# STM32L4R5 register map
File version: 2.4
CPU: CM4 r0p1, little endian, MPU, FPU, 4 interrupt priority bits
Registers are 32-bit, read-write, reset 0x0 unless marked. A register's access mark holds for its fields unless they carry their own. Offsets are from the block's base; [hi:lo] are bit positions; {n}, {i} and the like mark numbered series.

## FLASH
Base 0x40022000
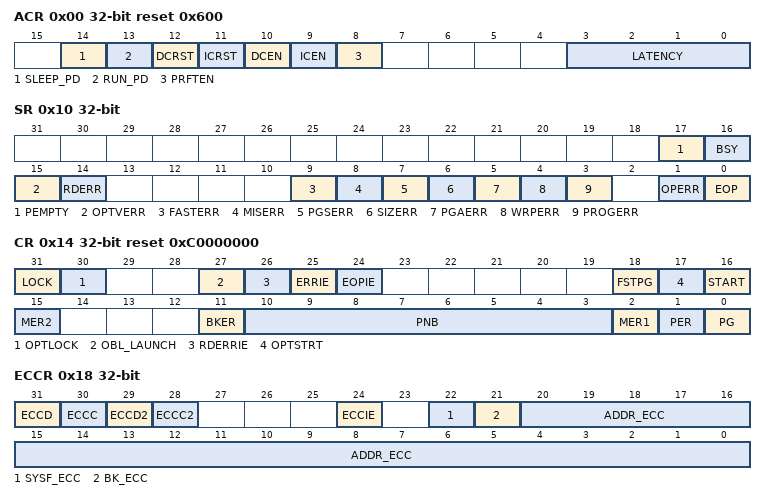
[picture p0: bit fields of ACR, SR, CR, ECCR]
0x00 ACR reset 0x600 — Access control register
  [14] SLEEP_PD — Flash Power-down mode during Low-power sleep mode
    0=Idle (Flash in idle mode during Sleep and Low-power sleep modes); 1=PowerDown (Flash in Power-down mode during Sleep and Low-power sleep modes)
  [13] RUN_PD — Flash Power-down mode during Low-power run mode
    0=Idle (Flash in idle mode); 1=PowerDown (Flash in Power-down mode)
  [12] DCRST — Data cache reset
    0=NotReset (Data cache is not reset); 1=Reset (Data cache is reset)
  [11] ICRST — Instruction cache reset
    0=NotReset (Instruction cache is not reset); 1=Reset (Instruction cache is reset)
  [10] DCEN — Data cache enable
    0=Disabled (Data cache is disabled); 1=Enabled (Data cache is enabled)
  [9] ICEN — Instruction cache enable
    0=Disabled (Instruction cache is disabled); 1=Enabled (Instruction cache is enabled)
  [8] PRFTEN — Prefetch enable
    0=Disabled (Prefetch is disabled); 1=Enabled (Prefetch is enabled)
  [3:0] LATENCY
    {v}=WS{v} ({v} wait states) (v=0..15)
0x04 PDKEYR wo — Power down key register
  [31:0] PDKEYR — RUN_PD in FLASH_ACR key
0x08 KEYR wo — Flash key register
0x0C OPTKEYR wo — Option byte key register
  [31:0] OPTKEYR — Option byte key
0x10 SR access per field — Status register
  [17] PEMPTY rw — Program EMPTY
    0=Toggling (The bit value is toggling); 1=NoEffect
  [16] BSY ro — Busy
    0=NotBusy; 1=Busy
  [15] OPTVERR rw — Option validity error
    on read: 0=NoError; 1=Error (Set by hardware when the options read may not be the one configured by the user. If option haven’t been properly loaded, OPTVERR is set again after each system reset) | on write: 1=Cleared by writing 1
  [14] RDERR rw — PCROP read error
    on read: 0=NoError; 1=Error (Set by hardware when an address to be read through the D-bus belongs to a read protected area of the Flash (PCROP protection)) | on write: 1=Cleared by writing 1
  [9] FASTERR rw — Fast programming error
    on read: 0=NoError; 1=Error (Set by hardware when a fast programming sequence (activated by FSTPG) is interrupted due to an error (alignment, size, write protection or data miss). The corresponding status bit (PGAERR, SIZERR, WRPERR or MISSERR) is set at the same time) | on write: 1=Cleared by writing 1
  [8] MISERR rw — Fast programming data miss error
    on read: 0=NoError; 1=Error (In fast programming mode, 32 double words must be sent to Flash successively, and the new data must be sent to the Flash logic control before the current data is fully programmed. MISSERR is set by hardware when the new data is not present in time) | on write: 1=Cleared by writing 1
  [7] PGSERR rw — Programming sequence error
    on read: 0=NoError; 1=Error (Set by hardware when a write access to the Flash memory is performed by the code while PG or FSTPG have not been set previously. Set also by hardware when PROGERR, SIZERR, PGAERR, WRPERR, MISSERR or FASTERR is set due to a previous programming error. Set also when trying to perform bank erase when DBANK=0 (or DB1M = 0)) | on write: 1=Cleared by writing 1
  [6] SIZERR rw — Size error
    on read: 0=NoError; 1=Error (Set by hardware when the size of the access is a byte or half-word during a program or a fast program sequence. Only double word programming is allowed (consequently: word access)) | on write: 1=Cleared by writing 1
  [5] PGAERR rw — Programming alignment error
    on read: 0=NoError; 1=Error (Set by hardware when the data to program cannot be contained in the same 64-bit Flash memory row in case of standard programming, or if there is a change of page during fast programming) | on write: 1=Cleared by writing 1
  [4] WRPERR rw — Write protected error
    on read: 0=NoError; 1=Error (Set by hardware when an address to be erased/programmed belongs to a writeprotected part (by WRP, PCROP or RDP level 1) of the Flash memory) | on write: 1=Cleared by writing 1
  [3] PROGERR rw — Programming error
    on read: 0=NoError; 1=Error (Set by hardware when a double-word address to be programmed contains a value different from '0xFFFF FFFF' before programming, except if the data to write is '0x0000 0000') | on write: 1=Cleared by writing 1
  [1] OPERR rw — Operation error
    on read: 0=NoError; 1=Error (Set by hardware when a Flash memory operation (program / erase) completes unsuccessfully) | on write: 1=Cleared by writing 1
  [0] EOP rw — End of operation
    on read: 0=NoError; 1=Error (Set by hardware when one or more Flash memory operation (programming / erase) has been completed successfully) | on write: 1=Cleared by writing 1
0x14 CR reset 0xC0000000 — Flash control register
  [31] LOCK — FLASH_CR Lock
    on read: 0=Unlocked (FLASH_CR register is unlocked); 1=Locked (FLASH_CR register is locked) | on write: 1=Set (This bit is set only. When set, the FLASH_CR register is locked)
  [30] OPTLOCK — Options Lock
    on read: 0=Unlocked (Option page is unlocked); 1=Locked (All bits concerning user option in FLASH_CR register and so option page are locked) | on write: 1=Set (This bit is set only. When set, all bits concerning user option in FLASH_CR register and so option page are locked)
  [27] OBL_LAUNCH — Force the option byte loading
    on read: 0=Complete (Option byte loading complete); 1=Requested (Option byte loading requested) | on write: 1=Set (Force option byte reloading)
  [26] RDERRIE — PCROP read error interrupt enable
    0=Disabled (PCROP read error interrupt disabled); 1=Enabled (PCROP read error interrupt enabled)
  [25] ERRIE — Error interrupt enable
    0=Disabled (Error interrupt generation disabled); 1=Enabled (Error interrupt generation enabled)
  [24] EOPIE — End of operation interrupt enable
    0=Disabled (End of operation interrupt disabled); 1=Enabled (End of operation interrupt enabled)
  [18] FSTPG — Fast programming
    0=Disabled (Fast programming disabled); 1=Enabled (Fast programming enabled)
  [17] OPTSTRT — Options modification start
    on read: 0=Complete (Cleared when BSY bit is cleared in SR); 1=Requested (Options modification requested) | on write: 1=Set (This bit triggers an options operation when set)
  [16] START
    on read: 0=Complete (Cleared when BSY bit is cleared in SR); 1=Requested (Erase operation requested) | on write: 1=Start (Trigger an erase operation)
  [15] MER2 — Bank 2 Mass erase
    on write: 1=MassErase (This bit triggers the bank 2 mass erase (all bank 2 user pages) when set)
  [11] BKER — Bank erase
    0=Bank 1 is selected for page erase; 1=Bank 2 is selected for page erase
  [10:3] PNB — Page number
  [2] MER1 — Bank 1 Mass erase
    on write: 1=MassErase (This bit triggers the bank 1 mass erase (all bank 1 user pages) when set)
  [1] PER — Page erase
    0=Disabled (Page erase disabled); 1=Enabled (Page erase enabled)
  [0] PG — Programming
    0=Disabled (Flash programming disabled); 1=Enabled (Flash programming enabled)
0x18 ECCR access per field — Flash ECC register
  [31] ECCD rw — ECC detection
    on read: 0=NoError (No double ECC errors detected on LSB); 1=Error (Set by hardware when two ECC errors have been detected on LSB) | on write: 1=Cleared by writing 1
  [30] ECCC rw — ECC correction
    on read: 0=NoError (No ECC error detected on LSB); 1=Error (Set by hardware when one ECC errors have been detected and corrected on LSB) | on write: 1=Cleared by writing 1
  [29] ECCD2 rw — ECC2 detection
    on read: 0=NoError (No double ECC errors detected on MSB); 1=Error (Set by hardware when two ECC errors have been detected on MSB) | on write: 1=Cleared by writing 1
  [28] ECCC2 rw — ECC correction
    on read: 0=NoError (No ECC error detected on MSB); 1=Error (Set by hardware when one ECC errors have been detected and corrected on MSB) | on write: 1=Cleared by writing 1
  [24] ECCIE rw — ECC correction interrupt enable
    0=Disabled (ECCC interrupt disabled); 1=Enabled (ECCC interrupt enabled)
  [22] SYSF_ECC ro — System Flash ECC fail
    1=InSystemFlash (This bit indicates that the ECC error correction or double ECC error detection is located in the System Flash)
  [21] BK_ECC ro — ECC fail bank
    0=Bank1; 1=Bank2
  [20:0] ADDR_ECC ro — ECC fail address
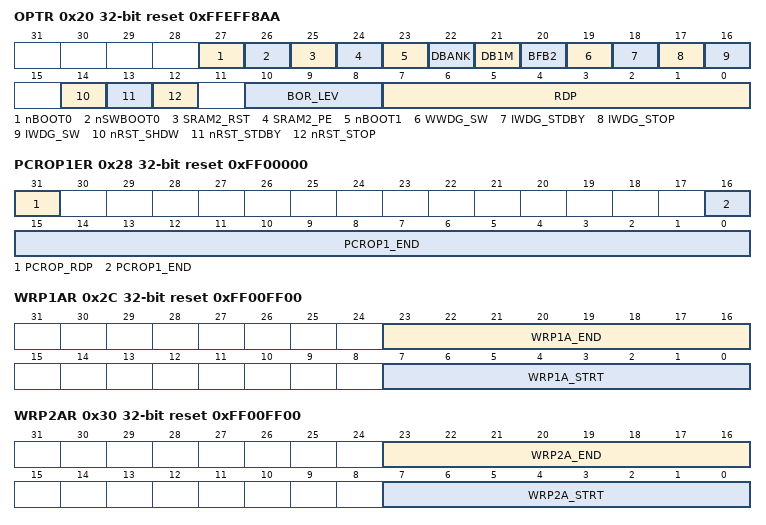
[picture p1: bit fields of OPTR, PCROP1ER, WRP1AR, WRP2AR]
0x20 OPTR reset 0xFFEFF8AA — Flash option register
  [27] nBOOT0 — nBOOT0 option bit
    0=Disabled (nBOOT0 = 0); 1=Enabled (nBOOT0 = 1)
  [26] nSWBOOT0 — Software BOOT0
    0=OptionBit (BOOT0 taken from the option bit nBOOT0); 1=Pin (BOOT0 taken from PH3/BOOT0 pin)
  [25] SRAM2_RST — SRAM2 Erase when system reset
    0=Enabled (SRAM2 erased when a system reset occurs); 1=Disabled (SRAM2 is not erased when a system reset occurs)
  [24] SRAM2_PE — SRAM2 parity check enable
    0=Enabled (SRAM2 parity check enabled); 1=Disabled (SRAM2 parity check disabled)
  [23] nBOOT1 — Boot configuration
  [22] DBANK
    0=Single-bank mode with 128 bits data read width; 1=Dual-bank mode with 64 bits data
  [21] DB1M — Dual-bank on 1 Mbyte Flash memory devices
    0=SingleBank (Single Flash contiguous address in Bank 1); 1=Dual-bank Flash with contiguous addresses
  [20] BFB2 — Dual-bank boot
    0=Disabled (Dual-bank boot disabled); 1=Enabled (Dual-bank boot enabled)
  [19] WWDG_SW — Window watchdog selection
    0=Hardware window watchdog; 1=Software window watchdog
  [18] IWDG_STDBY — Independent watchdog counter freeze in Standby mode
    0=Frozen (Independent watchdog counter is frozen in Standby mode); 1=Running (Independent watchdog counter is running in Standby mode)
  [17] IWDG_STOP — Independent watchdog counter freeze in Stop mode
    0=Frozen (Independent watchdog counter is frozen in Stop mode); 1=Running (Independent watchdog counter is running in Stop mode)
  [16] IWDG_SW — Independent watchdog selection
    0=Hardware independent watchdog; 1=Software independent watchdog
  [14] nRST_SHDW
  [13] nRST_STDBY
  [12] nRST_STOP
  [10:8] BOR_LEV — BOR reset Level
  [7:0] RDP — Read protection level
0x24 PCROP1SR reset 0xFFFFFFFF — Flash Bank 1 PCROP Start address register
  [16:0] PCROP1_STRT — Bank 1 PCROP area start offset
0x28 PCROP1ER reset 0xFF00000 — Flash Bank 1 PCROP End address register
  [31] PCROP_RDP — PCROP area preserved when RDP level decreased
    0=Disabled (PCROP area is not erased when the RDP level is decreased from Level 1 to Level 0); 1=Enabled (PCROP area is erased when the RDP level is decreased from Level 1 to Level 0)
  [16:0] PCROP1_END — Bank 1 PCROP area end offset
0x2C WRP1AR reset 0xFF00FF00 — Flash Bank 1 WRP area A address register
  [23:16] WRP1A_END — Bank 1 WRP first area A end offset
  [7:0] WRP1A_STRT — Bank 1 WRP first area start offset
0x30 WRP2AR reset 0xFF00FF00 — Flash WRP2 area A address register
  [23:16] WRP2A_END — WRP first area A end offset
  [7:0] WRP2A_STRT — WRP first area A start offset
0x44 PCROP2SR reset 0xFFFFFFFF — Flash PCROP2 Start address register
  [16:0] PCROP2_STRT — PCROP area start offset
0x48 PCROP2ER reset 0xFF00000 — Flash PCROP2 End address register
  [16:0] PCROP2_END — Bank 2 PCROP area end offset
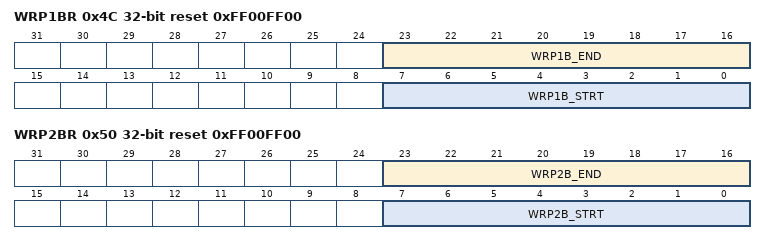
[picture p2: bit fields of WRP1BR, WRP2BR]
0x4C WRP1BR reset 0xFF00FF00 — Flash WRP1 area B address register
  [23:16] WRP1B_END — Bank 2 WRP first area A end offset
  [7:0] WRP1B_STRT — Bank 2 WRP first area A start offset
0x50 WRP2BR reset 0xFF00FF00 — Flash Bank 2 WRP area B address register
  [23:16] WRP2B_END — Bank 2 WRP second area B end offset
  [7:0] WRP2B_STRT — Bank 2 WRP second area B start offset
0x130 CFGR — Flash configuration register
  [0] LVEN — Low voltage enable
    0=Disabled (Flash low voltage disabled); 1=Enabled (Flash low voltage enabled)
